# bao1x register map
Vendor: baochip; File version: 1.0
Registers are 32-bit, read-write, reset 0x0 unless marked. A register's access mark holds for its fields unless they carry their own. Offsets are from the block's base; [hi:lo] are bit positions.

## IRQARRAY8
Base 0xE0016000
0x00 EV_SOFT — Software interrupt trigger register. ) Bits set to `1` will trigger an interrupt. Interrupts trigger on write, but the value will persist in the register, allowing software to determine if a software interrupt was triggered by reading back the register. Software is responsible for clearing the register to 0. Repeated `1` writes without clearing will still trigger an interrupt.
  [15:0] trigger
0x04 EV_EDGE_TRIGGERED — If a bit is set to 1, then the hardware trigger is edge-triggered
  [15:0] use_edge
0x08 EV_POLARITY — If a bit is set to 1, then the polarity is rising edge triggered; 0 is falling edge triggered. Bit is ignored if `edge_triggered` is 0.
  [15:0] rising
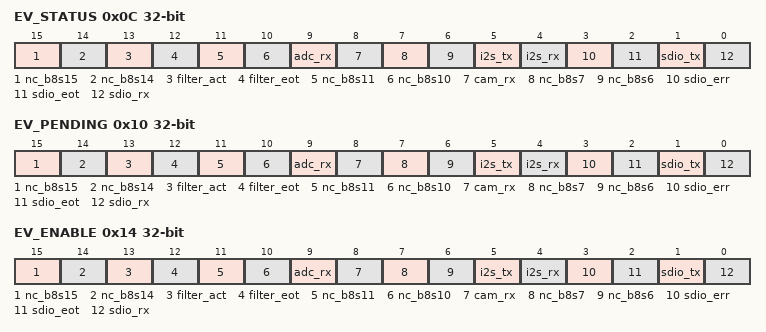
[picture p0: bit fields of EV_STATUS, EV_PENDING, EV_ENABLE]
0x0C EV_STATUS — `1` when a "nc_b8s15" event occurs. This event uses an `EventSourceFlex` form of triggering
  [15] nc_b8s15 — Level of the ``nc_b8s15`` event
  [14] nc_b8s14 — Level of the ``nc_b8s14`` event
  [13] filter_act — Level of the ``filter_act`` event
  [12] filter_eot — Level of the ``filter_eot`` event
  [11] nc_b8s11 — Level of the ``nc_b8s11`` event
  [10] nc_b8s10 — Level of the ``nc_b8s10`` event
  [9] adc_rx — Level of the ``adc_rx`` event
  [8] cam_rx — Level of the ``cam_rx`` event
  [7] nc_b8s7 — Level of the ``nc_b8s7`` event
  [6] nc_b8s6 — Level of the ``nc_b8s6`` event
  [5] i2s_tx — Level of the ``i2s_tx`` event
  [4] i2s_rx — Level of the ``i2s_rx`` event
  [3] sdio_err — Level of the ``sdio_err`` event
  [2] sdio_eot — Level of the ``sdio_eot`` event
  [1] sdio_tx — Level of the ``sdio_tx`` event
  [0] sdio_rx — Level of the ``sdio_rx`` event
0x10 EV_PENDING — `1` when a "nc_b8s15" event occurs. This event uses an `EventSourceFlex` form of triggering
  [15] nc_b8s15 — `1` when a "nc_b8s15" event occurs. This event uses an `EventSourceFlex` form of triggering
  [14] nc_b8s14 — `1` when a "nc_b8s14" event occurs. This event uses an `EventSourceFlex` form of triggering
  [13] filter_act — `1` when a "filter_act" event occurs. This event uses an `EventSourceFlex` form of triggering
  [12] filter_eot — `1` when a "filter_eot" event occurs. This event uses an `EventSourceFlex` form of triggering
  [11] nc_b8s11 — `1` when a "nc_b8s11" event occurs. This event uses an `EventSourceFlex` form of triggering
  [10] nc_b8s10 — `1` when a "nc_b8s10" event occurs. This event uses an `EventSourceFlex` form of triggering
  [9] adc_rx — `1` when a "adc_rx" event occurs. This event uses an `EventSourceFlex` form of triggering
  [8] cam_rx — `1` when a "cam_rx" event occurs. This event uses an `EventSourceFlex` form of triggering
  [7] nc_b8s7 — `1` when a "nc_b8s7" event occurs. This event uses an `EventSourceFlex` form of triggering
  [6] nc_b8s6 — `1` when a "nc_b8s6" event occurs. This event uses an `EventSourceFlex` form of triggering
  [5] i2s_tx — `1` when a "i2s_tx" event occurs. This event uses an `EventSourceFlex` form of triggering
  [4] i2s_rx — `1` when a "i2s_rx" event occurs. This event uses an `EventSourceFlex` form of triggering
  [3] sdio_err — `1` when a "sdio_err" event occurs. This event uses an `EventSourceFlex` form of triggering
  [2] sdio_eot — `1` when a "sdio_eot" event occurs. This event uses an `EventSourceFlex` form of triggering
  [1] sdio_tx — `1` when a "sdio_tx" event occurs. This event uses an `EventSourceFlex` form of triggering
  [0] sdio_rx — `1` when a "sdio_rx" event occurs. This event uses an `EventSourceFlex` form of triggering
0x14 EV_ENABLE — `1` when a "nc_b8s15" event occurs. This event uses an `EventSourceFlex` form of triggering
  [15] nc_b8s15 — Write a ``1`` to enable the ``nc_b8s15`` Event
  [14] nc_b8s14 — Write a ``1`` to enable the ``nc_b8s14`` Event
  [13] filter_act — Write a ``1`` to enable the ``filter_act`` Event
  [12] filter_eot — Write a ``1`` to enable the ``filter_eot`` Event
  [11] nc_b8s11 — Write a ``1`` to enable the ``nc_b8s11`` Event
  [10] nc_b8s10 — Write a ``1`` to enable the ``nc_b8s10`` Event
  [9] adc_rx — Write a ``1`` to enable the ``adc_rx`` Event
  [8] cam_rx — Write a ``1`` to enable the ``cam_rx`` Event
  [7] nc_b8s7 — Write a ``1`` to enable the ``nc_b8s7`` Event
  [6] nc_b8s6 — Write a ``1`` to enable the ``nc_b8s6`` Event
  [5] i2s_tx — Write a ``1`` to enable the ``i2s_tx`` Event
  [4] i2s_rx — Write a ``1`` to enable the ``i2s_rx`` Event
  [3] sdio_err — Write a ``1`` to enable the ``sdio_err`` Event
  [2] sdio_eot — Write a ``1`` to enable the ``sdio_eot`` Event
  [1] sdio_tx — Write a ``1`` to enable the ``sdio_tx`` Event
  [0] sdio_rx — Write a ``1`` to enable the ``sdio_rx`` Event
